VERSION ""

NS_ :

BS_:

BU_:

BO_ 3221225472 VECTOR__INDEPENDENT_SIG_MSG: 0 Vector__XXX
 SG_ Gear : 0|2@1+ (1,0) [0|3] "" Vector__XXX

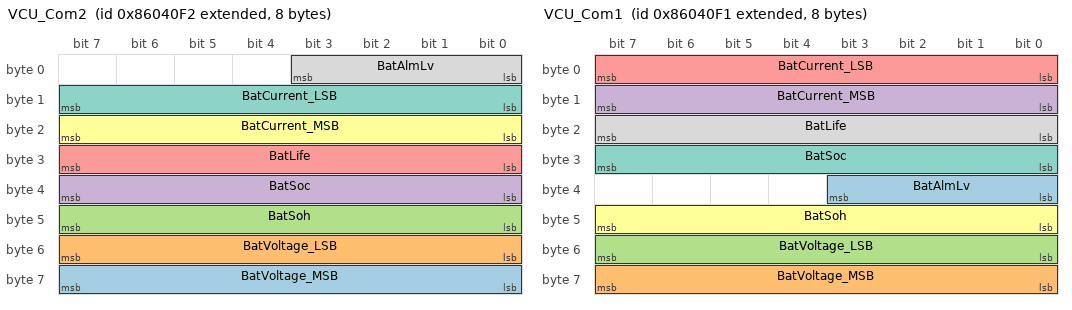
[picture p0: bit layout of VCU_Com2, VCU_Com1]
BO_ 2288009458 VCU_Com2: 8 Vector__XXX
 SG_ BatVoltage_MSB : 56|8@1+ (1,0) [0|255] "V" Vector__XXX
 SG_ BatVoltage_LSB : 48|8@1+ (1,0) [0|255] "V" Vector__XXX
 SG_ BatSoh : 40|8@1+ (1,0) [0|255] "%" Vector__XXX
 SG_ BatSoc : 32|8@1+ (1,0) [0|255] "%" Vector__XXX
 SG_ BatLife : 24|8@1+ (1,0) [0|255] "" Vector__XXX
 SG_ BatCurrent_MSB : 16|8@1+ (1,0) [0|255] "A" Vector__XXX
 SG_ BatCurrent_LSB : 8|8@1+ (1,0) [0|255] "A" Vector__XXX
 SG_ BatAlmLv : 0|4@1+ (1,0) [0|15] "" Vector__XXX

BO_ 2288009457 VCU_Com1: 8 Vector__XXX
 SG_ BatAlmLv : 32|4@1+ (1,0) [0|15] "" Vector__XXX
 SG_ BatVoltage_MSB : 56|8@1+ (1,0) [0|255] "V" Vector__XXX
 SG_ BatVoltage_LSB : 48|8@1+ (1,0) [0|255] "V" Vector__XXX
 SG_ BatCurrent_MSB : 8|8@1+ (1,0) [0|255] "A" Vector__XXX
 SG_ BatCurrent_LSB : 0|8@1+ (1,0) [0|255] "A" Vector__XXX
 SG_ BatSoh : 40|8@1+ (1,0) [0|255] "%" Vector__XXX
 SG_ BatSoc : 24|8@1+ (1,0) [0|255] "%" Vector__XXX
 SG_ BatLife : 16|8@1+ (1,0) [0|255] "" Vector__XXX

BO_ 2147483989 DashtoVCU: 8 Vector__XXX
 SG_ Dash_Key : 0|8@1+ (1,0) [0|255] "" Vector__XXX

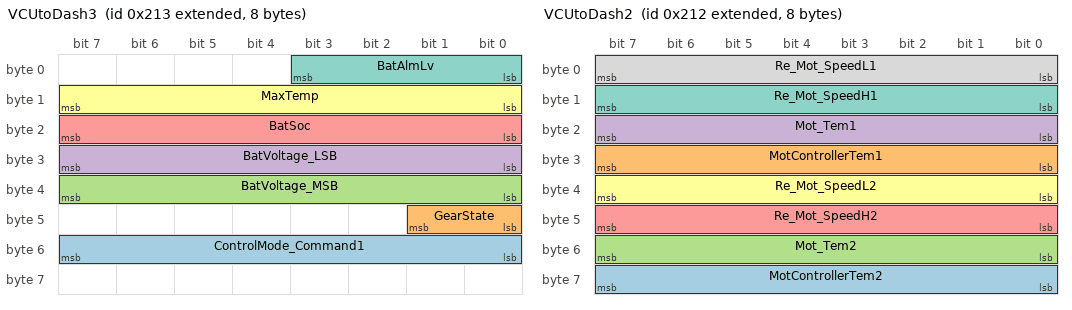
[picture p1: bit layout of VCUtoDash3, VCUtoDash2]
BO_ 2147484179 VCUtoDash3: 8 Vector__XXX
 SG_ ControlMode_Command1 : 48|8@1+ (1,0) [0|255] "" Vector__XXX
 SG_ GearState : 40|2@1+ (1,0) [0|3] "" Vector__XXX
 SG_ BatVoltage_MSB : 32|8@1+ (1,0) [0|255] "V" Vector__XXX
 SG_ BatVoltage_LSB : 24|8@1+ (1,0) [0|255] "V" Vector__XXX
 SG_ BatSoc : 16|8@1+ (1,0) [0|255] "%" Vector__XXX
 SG_ MaxTemp : 8|8@1+ (1,0) [0|255] "¡æ" Vector__XXX
 SG_ BatAlmLv : 0|4@1+ (1,0) [0|15] "" Vector__XXX

BO_ 2147484178 VCUtoDash2: 8 Vector__XXX
 SG_ MotControllerTem2 : 56|8@1+ (1,0) [0|255] "¡æ" Vector__XXX
 SG_ MotControllerTem1 : 24|8@1+ (1,0) [0|255] "¡æ" Vector__XXX
 SG_ Mot_Tem2 : 48|8@1+ (1,0) [0|255] "" Vector__XXX
 SG_ Mot_Tem1 : 16|8@1+ (1,0) [0|255] "" Vector__XXX
 SG_ Re_Mot_SpeedH2 : 40|8@1+ (1,0) [0|255] "" Vector__XXX
 SG_ Re_Mot_SpeedL2 : 32|8@1+ (1,0) [0|255] "" Vector__XXX
 SG_ Re_Mot_SpeedH1 : 8|8@1+ (1,0) [0|255] "" Vector__XXX
 SG_ Re_Mot_SpeedL1 : 0|8@1+ (1,0) [0|255] "" Vector__XXX

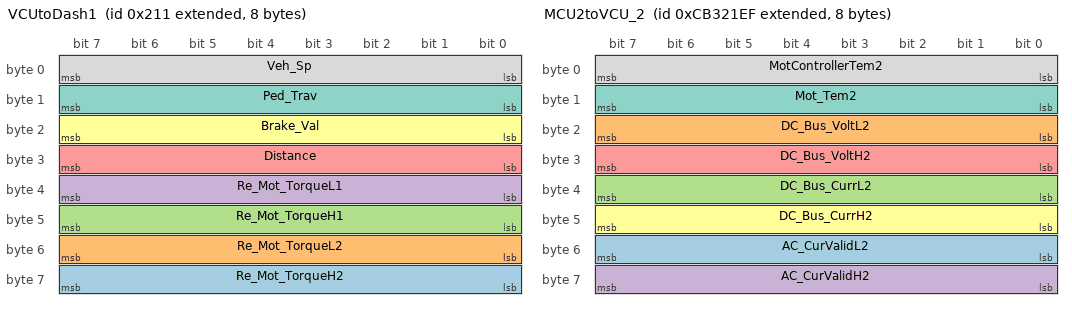
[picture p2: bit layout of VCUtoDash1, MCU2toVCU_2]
BO_ 2147484177 VCUtoDash1: 8 Vector__XXX
 SG_ Re_Mot_TorqueH2 : 56|8@1+ (1,0) [0|255] "" Vector__XXX
 SG_ Re_Mot_TorqueL2 : 48|8@1+ (1,0) [0|255] "" Vector__XXX
 SG_ Re_Mot_TorqueH1 : 40|8@1+ (1,0) [0|255] "" Vector__XXX
 SG_ Re_Mot_TorqueL1 : 32|8@1+ (1,0) [0|255] "" Vector__XXX
 SG_ Distance : 24|8@1+ (1,0) [0|255] "" Vector__XXX
 SG_ Brake_Val : 16|8@1+ (1,0) [0|255] "" Vector__XXX
 SG_ Ped_Trav : 8|8@1+ (1,0) [0|255] "" Vector__XXX
 SG_ Veh_Sp : 0|8@1+ (1,0) [0|255] "" Vector__XXX

BO_ 2360549871 MCU2toVCU_2: 8 Vector__XXX
 SG_ AC_CurValidL2 : 48|8@1+ (1,0) [0|255] "" Vector__XXX
 SG_ DC_Bus_VoltL2 : 16|8@1+ (1,0) [0|255] "" Vector__XXX
 SG_ DC_Bus_CurrL2 : 32|8@1+ (1,0) [0|255] "" Vector__XXX
 SG_ AC_CurValidH2 : 56|8@1+ (1,0) [0|255] "" Vector__XXX
 SG_ DC_Bus_VoltH2 : 24|8@1+ (1,0) [0|255] "" Vector__XXX
 SG_ DC_Bus_CurrH2 : 40|8@1+ (1,0) [0|255] "" Vector__XXX
 SG_ Mot_Tem2 : 8|8@1+ (1,0) [0|255] "" Vector__XXX
 SG_ MotControllerTem2 : 0|8@1+ (1,-50) [-50|205] "¡æ" Vector__XXX

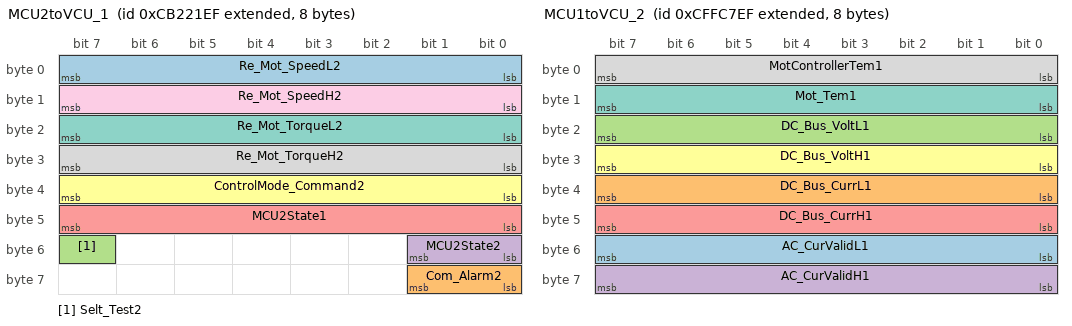
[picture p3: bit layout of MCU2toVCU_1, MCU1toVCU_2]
BO_ 2360484335 MCU2toVCU_1: 8 Vector__XXX
 SG_ Re_Mot_SpeedL2 : 0|8@1+ (1,0) [-128|127] "" Vector__XXX
 SG_ Com_Alarm2 : 56|2@1+ (1,0) [0|3] "" Vector__XXX
 SG_ Selt_Test2 : 55|1@1+ (1,0) [0|1] "" Vector__XXX
 SG_ MCU2State2 : 48|2@1+ (1,0) [0|3] "" Vector__XXX
 SG_ MCU2State1 : 40|8@1+ (1,0) [0|255] "" Vector__XXX
 SG_ ControlMode_Command2 : 32|8@1+ (1,0) [0|255] "" Vector__XXX
 SG_ Re_Mot_TorqueL2 : 16|8@1+ (1,0) [0|255] "" Vector__XXX
 SG_ Re_Mot_TorqueH2 : 24|8@1+ (1,0) [0|255] "" Vector__XXX
 SG_ Re_Mot_SpeedH2 : 8|8@1+ (1,0) [-128|127] "" Vector__XXX

BO_ 2365573103 MCU1toVCU_2: 8 Vector__XXX
 SG_ AC_CurValidL1 : 48|8@1+ (1,0) [0|255] "" Vector__XXX
 SG_ DC_Bus_CurrL1 : 32|8@1+ (1,0) [0|255] "" Vector__XXX
 SG_ DC_Bus_VoltL1 : 16|8@1+ (1,0) [0|255] "" Vector__XXX
 SG_ AC_CurValidH1 : 56|8@1+ (1,0) [0|255] "" Vector__XXX
 SG_ DC_Bus_CurrH1 : 40|8@1+ (1,0) [0|255] "" Vector__XXX
 SG_ DC_Bus_VoltH1 : 24|8@1+ (1,0) [0|255] "" Vector__XXX
 SG_ Mot_Tem1 : 8|8@1+ (1,0) [0|255] "" Vector__XXX
 SG_ MotControllerTem1 : 0|8@1+ (1,-50) [-50|205] "¡æ" Vector__XXX

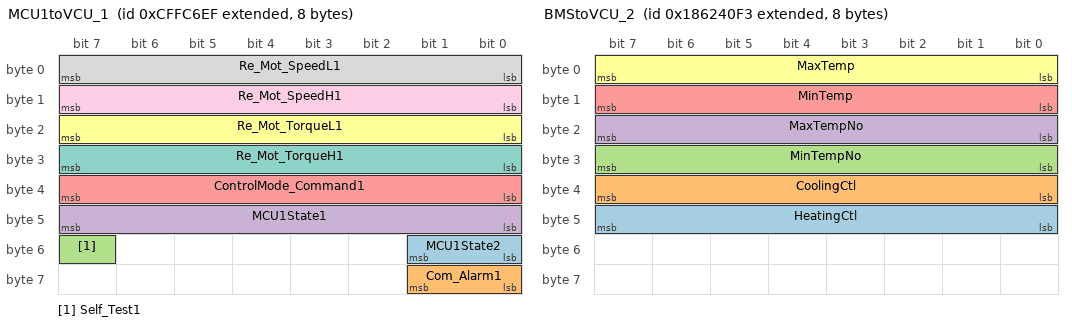
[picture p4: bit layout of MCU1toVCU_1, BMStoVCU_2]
BO_ 2365572847 MCU1toVCU_1: 8 Vector__XXX
 SG_ MCU1State2 : 48|2@1+ (1,0) [0|3] "" Vector__XXX
 SG_ Com_Alarm1 : 56|2@1+ (1,0) [0|3] "" Vector__XXX
 SG_ Self_Test1 : 55|1@1+ (1,0) [0|1] "" Vector__XXX
 SG_ MCU1State1 : 40|8@1+ (1,0) [0|255] "" Vector__XXX
 SG_ ControlMode_Command1 : 32|8@1+ (1,0) [0|255] "" Vector__XXX
 SG_ Re_Mot_TorqueL1 : 16|8@1+ (1,0) [0|255] "" Vector__XXX
 SG_ Re_Mot_TorqueH1 : 24|8@1+ (1,0) [0|255] "" Vector__XXX
 SG_ Re_Mot_SpeedL1 : 0|8@1+ (1,0) [0|255] "" Vector__XXX
 SG_ Re_Mot_SpeedH1 : 8|8@1+ (1,0) [0|255] "" Vector__XXX

BO_ 2556575987 BMStoVCU_2: 8 Vector__XXX
 SG_ HeatingCtl : 40|8@1+ (1,0) [0|255] "" Vector__XXX
 SG_ CoolingCtl : 32|8@1+ (1,0) [0|255] "" Vector__XXX
 SG_ MinTempNo : 24|8@1+ (1,0) [0|255] "" Vector__XXX
 SG_ MaxTempNo : 16|8@1+ (1,0) [0|255] "" Vector__XXX
 SG_ MinTemp : 8|8@1+ (1,-40) [-40|215] "¡æ" Vector__XXX
 SG_ MaxTemp : 0|8@1+ (1,-40) [-40|215] "¡æ" Vector__XXX

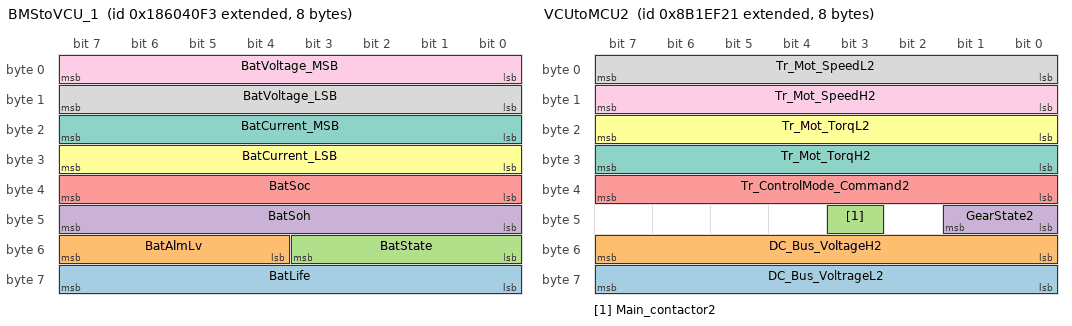
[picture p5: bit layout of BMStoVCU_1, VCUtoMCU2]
BO_ 2556444915 BMStoVCU_1: 8 Vector__XXX
 SG_ BatLife : 56|8@1+ (1,0) [0|255] "" Vector__XXX
 SG_ BatAlmLv : 52|4@1+ (1,0) [0|15] "" Vector__XXX
 SG_ BatState : 48|4@1+ (1,0) [0|15] "" Vector__XXX
 SG_ BatSoh : 40|8@1+ (1,0) [0|255] "%" Vector__XXX
 SG_ BatSoc : 32|8@1+ (1,0) [0|255] "%" Vector__XXX
 SG_ BatCurrent_LSB : 24|8@1+ (1,0) [0|255] "A" Vector__XXX
 SG_ BatCurrent_MSB : 16|8@1+ (1,0) [0|255] "A" Vector__XXX
 SG_ BatVoltage_LSB : 8|8@1+ (1,0) [0|255] "V" Vector__XXX
 SG_ BatVoltage_MSB : 0|8@1+ (1,0) [0|255] "V" Vector__XXX

BO_ 2293362465 VCUtoMCU2: 8 Vector__XXX
 SG_ DC_Bus_VoltrageL2 : 56|8@1+ (1,0) [0|255] "" Vector__XXX
 SG_ DC_Bus_VoltageH2 : 48|8@1+ (1,0) [0|255] "" Vector__XXX
 SG_ Main_contactor2 : 43|1@1+ (1,0) [0|1] "" Vector__XXX
 SG_ GearState2 : 40|2@1+ (1,0) [0|3] "" Vector__XXX
 SG_ Tr_ControlMode_Command2 : 32|8@1+ (1,0) [0|255] "" Vector__XXX
 SG_ Tr_Mot_TorqL2 : 16|8@1+ (1,0) [0|255] "" Vector__XXX
 SG_ Tr_Mot_TorqH2 : 24|8@1+ (1,0) [0|255] "" Vector__XXX
 SG_ Tr_Mot_SpeedL2 : 0|8@1+ (1,0) [0|255] "" Vector__XXX
 SG_ Tr_Mot_SpeedH2 : 8|8@1+ (1,0) [0|255] "" Vector__XXX

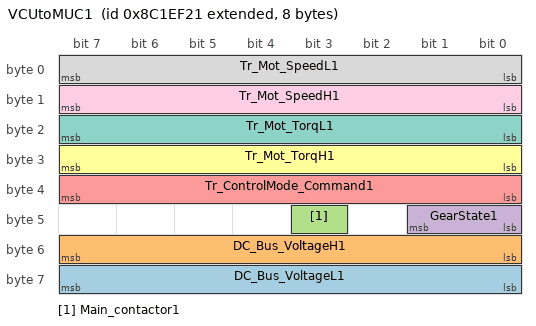
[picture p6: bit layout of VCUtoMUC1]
BO_ 2294411041 VCUtoMUC1: 8 Vector__XXX
 SG_ DC_Bus_VoltageL1 : 56|8@1+ (1,0) [0|255] "V" Vector__XXX
 SG_ DC_Bus_VoltageH1 : 48|8@1+ (1,0) [0|255] "" Vector__XXX
 SG_ Main_contactor1 : 43|1@1+ (1,0) [0|1] "" Vector__XXX
 SG_ GearState1 : 40|2@1+ (1,0) [0|3] "" Vector__XXX
 SG_ Tr_ControlMode_Command1 : 32|8@1+ (1,0) [0|255] "" Vector__XXX
 SG_ Tr_Mot_TorqH1 : 24|8@1+ (1,0) [0|255] "" Vector__XXX
 SG_ Tr_Mot_TorqL1 : 16|8@1+ (1,0) [0|255] "" Vector__XXX
 SG_ Tr_Mot_SpeedL1 : 0|8@1+ (1,0) [0|255] "" Vector__XXX
 SG_ Tr_Mot_SpeedH1 : 8|8@1+ (1,0) [0|255] "" Vector__XXX

CM_ BO_ 3221225472 "This is a message for not used signals, created by Vector CANdb++ DBC OLE DB Provider.";
BA_DEF_  "BusType" STRING ;
BA_DEF_DEF_  "BusType" "CAN";
